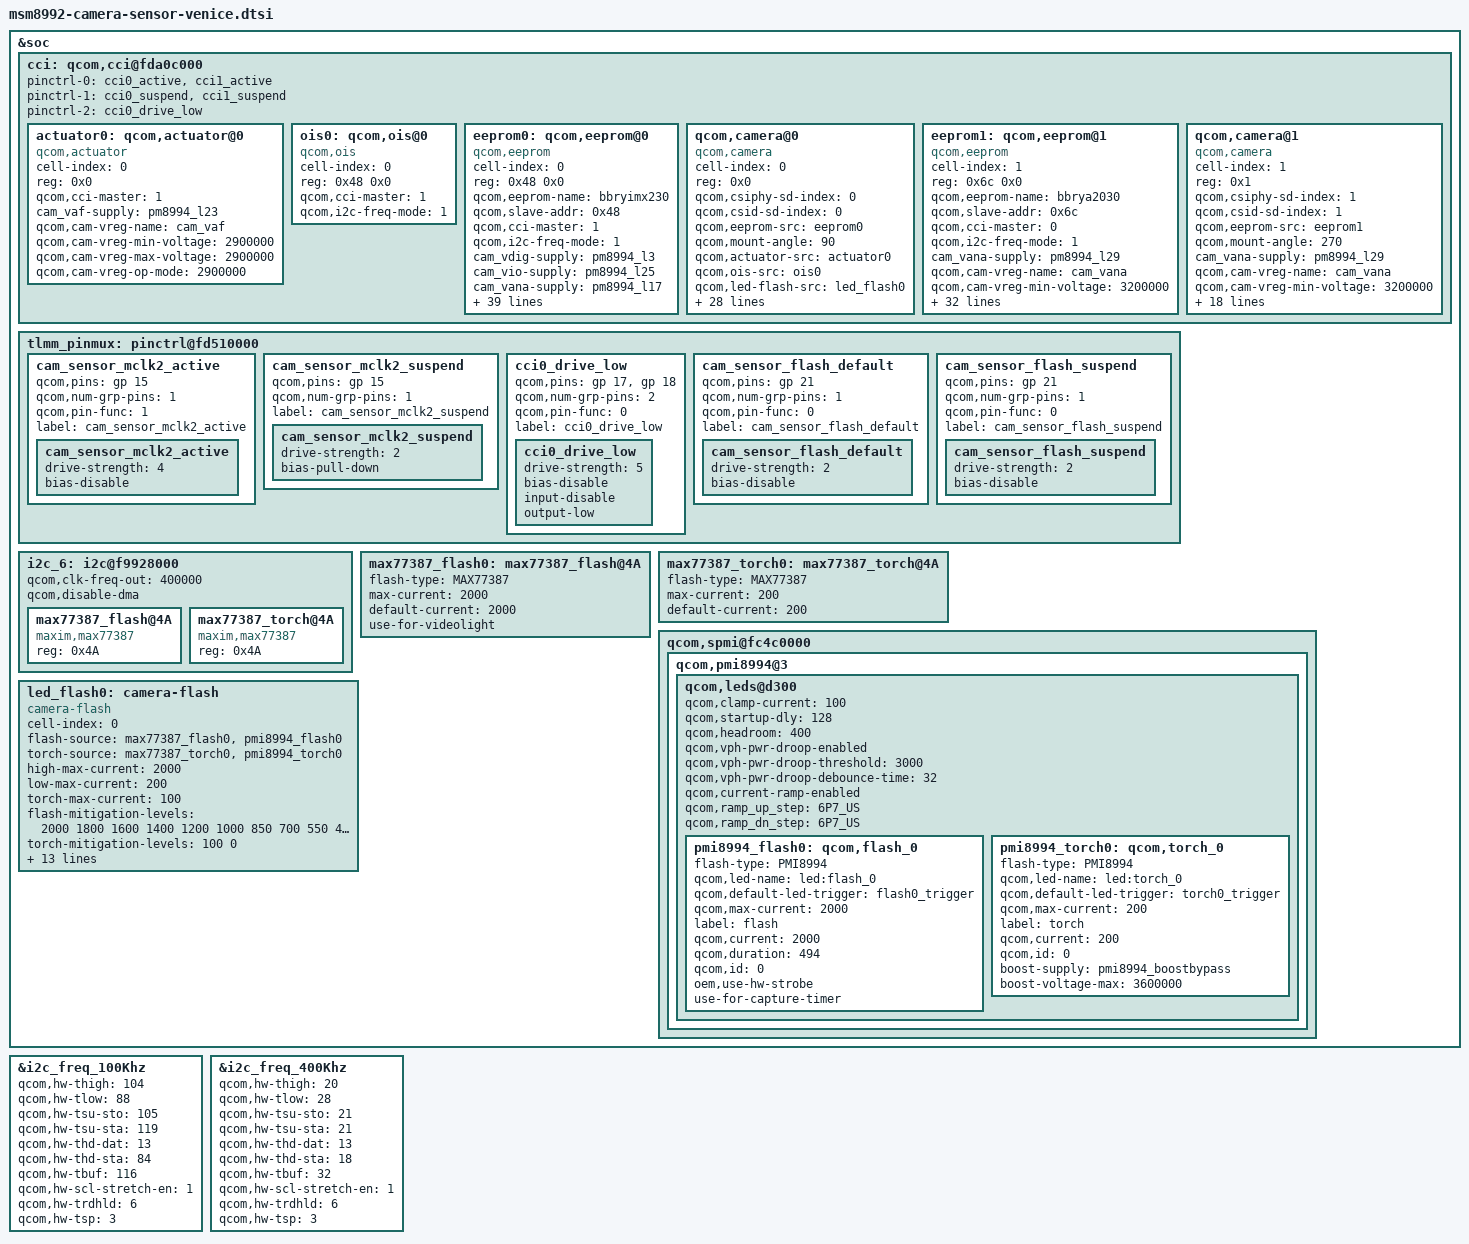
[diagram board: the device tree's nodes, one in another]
/*
 * Copyright (c) 2014, The Linux Foundation. All rights reserved.
 *
 * This program is free software; you can redistribute it and/or modify
 * it under the terms of the GNU General Public License version 2 and
 * only version 2 as published by the Free Software Foundation.
 *
 * This program is distributed in the hope that it will be useful,
 * but WITHOUT ANY WARRANTY; without even the implied warranty of
 * MERCHANTABILITY or FITNESS FOR A PARTICULAR PURPOSE.  See the
 * GNU General Public License for more details.
 */

&soc {
	cci: qcom,cci@fda0c000 {
		pinctrl-names = "cci_default", "cci_suspend", "cci0_pull_down";
			pinctrl-0 = <&cci0_active &cci1_active>;
			pinctrl-1 = <&cci0_suspend &cci1_suspend>;
			pinctrl-2 = <&cci0_drive_low>;
	};

	tlmm_pinmux: pinctrl@fd510000 {
		cam_sensor_mclk2_active {
			/* MCLK2 */
			qcom,pins = <&gp 15>;
			qcom,num-grp-pins = <1>;
			qcom,pin-func = <1>;
			label = "cam_sensor_mclk2_active";
			/* active state */
			cam_sensor_mclk2_active: cam_sensor_mclk2_active {
				drive-strength = <4>; /* 4 MA */
				bias-disable; /* No PULL */
			};
		};

		cam_sensor_mclk2_suspend {
			/* MCLK2 */
			qcom,pins = <&gp 15>;
			qcom,num-grp-pins = <1>;
			label = "cam_sensor_mclk2_suspend";
			/* suspend state */
			cam_sensor_mclk2_suspend: cam_sensor_mclk2_suspend {
				drive-strength = <2>; /* 2 MA */
				bias-pull-down; /* PULL DOWN */
			};
		};

		cci0_drive_low {
			/* CLK, DATA */
			qcom,pins = <&gp 17>, <&gp 18>;
			qcom,num-grp-pins = <2>;
			qcom,pin-func = <0>;
			label = "cci0_drive_low";
			/*pre suspended state */
			cci0_drive_low: cci0_drive_low {
				drive-strength = <5>; /* 5 MA */
				bias-disable; /* No PULL */
				input-disable;
				output-low;
			};
		};

		cam_sensor_flash_default {
			qcom,pins = <&gp 21>;
			qcom,num-grp-pins = <1>;
			qcom,pin-func = <0>;
			label = "cam_sensor_flash_default";
			cam_sensor_flash_default:cam_sensor_flash_default {
				drive-strength = <2>;
				bias-disable;
			};
		};

		cam_sensor_flash_suspend {
			qcom,pins = <&gp 21>;
			qcom,num-grp-pins = <1>;
			qcom,pin-func = <0>;
			label = "cam_sensor_flash_suspend";
			cam_sensor_flash_suspend:cam_sensor_flash_suspend {
				drive-strength = <2>;
				bias-disable;
			};
		};
	};

	i2c_6: i2c@f9928000 {
		qcom,clk-freq-out = <400000>;
		qcom,disable-dma;

		max77387_flash@4A {
			compatible = "maxim,max77387";
			reg = <0x4A>; /* i2c slave address */
		};

		max77387_torch@4A {
			compatible = "maxim,max77387";
			reg = <0x4A>; /* i2c slave address */
		};
	};

	max77387_flash0: max77387_flash@4A {
		flash-type = "MAX77387";
		max-current = <2000>;
		default-current = <2000>;
		use-for-videolight;
	};

	max77387_torch0: max77387_torch@4A {
		flash-type = "MAX77387";
		max-current = <200>;
		default-current = <200>;
	};

	qcom,spmi@fc4c0000 {
		qcom,pmi8994@3 {
			qcom,leds@d300 {
				qcom,clamp-current = <100>;
				qcom,startup-dly = <128>;
				qcom,headroom = <400>;
				qcom,vph-pwr-droop-enabled;
				qcom,vph-pwr-droop-threshold = <3000>;
				qcom,vph-pwr-droop-debounce-time = <32>;
				qcom,current-ramp-enabled;
				qcom,ramp_up_step = "6P7_US";
				qcom,ramp_dn_step = "6P7_US";
				/delete-property/ qcom,thermal-derate-enabled;
				/delete-property/ qcom,headroom-sense-ch0-enabled;
				/delete-property/ qcom,headroom-sense-ch1-enabled;
				/delete-property/ qcom,power-detect-enabled;

				pmi8994_flash0: qcom,flash_0 {
					flash-type = "PMI8994";
					qcom,led-name = "led:flash_0";
					qcom,default-led-trigger =
							"flash0_trigger";
					qcom,max-current = <2000>;
					label = "flash";
					qcom,current = <2000>;
					qcom,duration = <494>;
					qcom,id = <0>;
					oem,use-hw-strobe;
					use-for-capture-timer;
				};

				pmi8994_torch0: qcom,torch_0 {
					flash-type = "PMI8994";
					qcom,led-name = "led:torch_0";
					qcom,default-led-trigger =
							"torch0_trigger";
					qcom,max-current = <200>;
					label = "torch";
					qcom,current = <200>;
					qcom,id = <0>;
					boost-supply= <&pmi8994_boostbypass>;
					boost-voltage-max = <3600000>;
				};

				/delete-node/ pmi8994_torch1;
				/delete-node/ pmi8994_flash1;
			};
		};
	};

	led_flash0: camera-flash {
		cell-index = <0>;
		compatible = "camera-flash";
		flash-source = <&max77387_flash0 &pmi8994_flash0>;
		torch-source = <&max77387_torch0 &pmi8994_torch0>;
		high-max-current = <2000>;
		low-max-current = <200>;
		torch-max-current = <100>;
		flash-mitigation-levels = <2000 1800 1600 1400 1200 1000
						850 700 550 400 200 100 0>;
		torch-mitigation-levels = <100 0>;
		curve_mA_values = <0 100 200 400 550 700
								850 1000 1200 1400 1600 1800 2000>;
		/* relative flux values are 16.16 fixed point */
		curve_rel_flux_values = <0 5085 9510 18173 23917 29755
								35122 40113 46327 52448 57438 61487 65536>;
		preflash-divisor = <10>;

		pinctrl-names = "cam_flash_default", "cam_flash_suspend";
		pinctrl-0 = <&cam_sensor_flash_default>;
		pinctrl-1 = <&cam_sensor_flash_suspend>;
		gpios = <&msm_gpio 21 0>;
		qcom,gpio-flash-now = <0>;
		qcom,gpio-req-tbl-num = <0>;
		qcom,gpio-req-tbl-flags = <0>;
		qcom,gpio-req-tbl-label = "FLASH_NOW";
		vdd-supply = <&pm8994_l30>;
	};
};

&cci {
	actuator0: qcom,actuator@0 {
		cell-index = <0>;
		reg = <0x0>;
		compatible = "qcom,actuator";
		qcom,cci-master = <1>;
		cam_vaf-supply = <&pm8994_l23>;
		qcom,cam-vreg-name = "cam_vaf";
		qcom,cam-vreg-min-voltage = <2900000>;
		qcom,cam-vreg-max-voltage = <2900000>;
		qcom,cam-vreg-op-mode = <2900000>;
	};

	ois0: qcom,ois@0 {
		cell-index = <0>;
		reg = <0x48 0x0>;
		compatible = "qcom,ois";
		qcom,cci-master = <1>;
		qcom,i2c-freq-mode = <1>;
	};

	eeprom0: qcom,eeprom@0 {
		cell-index = <0>;
		reg = <0x48 0x0>;
		qcom,eeprom-name = "bbryimx230";
		compatible = "qcom,eeprom";
		qcom,slave-addr = <0x48>;
		qcom,cci-master = <1>;
		qcom,i2c-freq-mode = <1>;
		cam_vdig-supply = <&pm8994_l3>;
		cam_vio-supply = <&pm8994_l25>;
		cam_vana-supply = <&pm8994_l17>;
		cam_vaf-supply = <&pm8994_l23>;
		qcom,cam-vreg-name = "cam_vaf", "cam_vdig", "cam_vio", "cam_vana";
		qcom,cam-vreg-min-voltage = <2900000 1100000 1850000 2825000>;
		qcom,cam-vreg-max-voltage = <2900000 1100000 1850000 2825000>;
		qcom,cam-vreg-op-mode = <2900000 1100000 1850000 2825000>;
		qcom,gpio-no-mux = <0>;
		pinctrl-names = "cam_default", "cam_suspend";
		pinctrl-0 = <&cam_sensor_mclk0_active &cam_sensor_rear_active>;
		pinctrl-1 = <&cam_sensor_mclk0_suspend &cam_sensor_rear_suspend>;
		gpios = <&msm_gpio 13 0>,
			<&msm_gpio 92 0>;
		qcom,gpio-reset = <1>;
		qcom,gpio-req-tbl-num = <0 1>;
		qcom,gpio-req-tbl-flags = <1 0>;
		qcom,gpio-req-tbl-label = "CAMIF_MCLK0",
							"CAM_RESET0";
		qcom,cam-power-seq-type = "sensor_gpio",
			"sensor_vreg",
			"sensor_vreg",
			"sensor_vreg",
			"sensor_vreg",
			"sensor_clk",
			"sensor_gpio";
		qcom,cam-power-seq-val = "sensor_gpio_reset",
			"cam_vio",
			"cam_vaf",
			"cam_vana",
			"cam_vdig",
			"sensor_cam_mclk",
			"sensor_gpio_reset";
		qcom,cam-power-seq-cfg-val = <0 0 0 0 0 24000000 1>;
		qcom,cam-power-seq-delay = <1 4 4 4 4 4 40>;
		qcom,cam-powerdown-seq-type = "sensor_gpio",
			"sensor_gpio",
			"sensor_clk",
			"sensor_vreg",
			"sensor_vreg",
			"sensor_vreg",
			"sensor_vreg";
		qcom,cam-powerdown-seq-val = "sensor_gpio_reset",
			"sensor_gpio_reset",
			"sensor_cam_mclk",
			"cam_vdig",
			"cam_vana",
			"cam_vaf",
			"cam_vio";
		qcom,cam-powerdown-seq-cfg-val = <1 0 0 0 0 0 0 >;
		qcom,cam-powerdown-seq-delay = < 4 4 4 4 4 4 4>;
		status = "ok";
		clocks = <&clock_mmss clk_mclk0_clk_src>,
				<&clock_mmss clk_camss_mclk0_clk>;
		clock-names = "cam_src_clk", "cam_clk";
	};

	qcom,camera@0 {
		cell-index = <0>;
		compatible = "qcom,camera";
		reg = <0x0>;
		qcom,csiphy-sd-index = <0>;
		qcom,csid-sd-index = <0>;
		qcom,eeprom-src = <&eeprom0>;
		qcom,mount-angle = <90>;
		qcom,actuator-src = <&actuator0>;
		qcom,ois-src = <&ois0>;
		qcom,led-flash-src = <&led_flash0>;
		cam_vdig-supply = <&pm8994_l3>;
		cam_vio-supply = <&pm8994_l25>;
		cam_vana-supply = <&pm8994_l17>;
		cam_vaf-supply = <&pm8994_l23>;
		qcom,cam-vreg-name = "cam_vaf", "cam_vdig", "cam_vio", "cam_vana";
		qcom,cam-vreg-min-voltage = <2900000 1100000 1850000 2825000>;
		qcom,cam-vreg-max-voltage = <2900000 1100000 1850000 2825000>;
		qcom,cam-vreg-op-mode = <2900000 1100000 1850000 2825000>;
		qcom,gpio-no-mux = <0>;
		pinctrl-names = "cam_default", "cam_suspend";
		pinctrl-0 = <&cam_sensor_mclk0_active &cam_sensor_rear_active>;
		pinctrl-1 = <&cam_sensor_mclk0_suspend &cam_sensor_rear_suspend>;
		gpios = <&msm_gpio 13 0>,
			<&msm_gpio 92 0>;
		qcom,gpio-reset = <1>;
		qcom,gpio-req-tbl-num = <0 1>;
		qcom,gpio-req-tbl-flags = <1 0>;
		qcom,gpio-req-tbl-label = "CAMIF_MCLK0",
					  "CAM_RESET0";
		qcom,sensor-position = <0>;
		qcom,sensor-mode = <0>;
		qcom,cci-master = <1>;
		status = "ok";
		clocks = <&clock_mmss clk_mclk0_clk_src>,
				<&clock_mmss clk_camss_mclk0_clk>;
		clock-names = "cam_src_clk", "cam_clk";
	};

	eeprom1: qcom,eeprom@1 {
		cell-index = <1>;
		reg = <0x6c 0x0>;
		qcom,eeprom-name = "bbrya2030";
		compatible = "qcom,eeprom";
		qcom,slave-addr = <0x6c>;
		qcom,cci-master = <0>;
		qcom,i2c-freq-mode = <1>;
		cam_vana-supply = <&pm8994_l29>;
		qcom,cam-vreg-name = "cam_vana";
		qcom,cam-vreg-min-voltage = <3200000>;
		qcom,cam-vreg-max-voltage = <3200000>;
		qcom,cam-vreg-op-mode = <3200000>;
		qcom,gpio-no-mux = <0>;
		pinctrl-names = "cam_default", "cam_suspend";
		pinctrl-0 = <&cam_sensor_mclk2_active &cam_sensor_front_active>;
		pinctrl-1 = <&cam_sensor_mclk2_suspend &cam_sensor_front_suspend>;
		gpios = <&msm_gpio 15 0>,
			<&msm_gpio 104 0>;
		qcom,gpio-reset = <1>;
		qcom,gpio-req-tbl-num = <0 1>;
		qcom,gpio-req-tbl-flags = <1 0>;
		qcom,gpio-req-tbl-label = "CAMIF_MCLK2",
					  "CAM_RESET1";
		qcom,csi-lane-assign = <0x4320>;
		qcom,csi-lane-mask = <0x3>;
		qcom,cam-power-seq-type = "sensor_gpio",
			"sensor_vreg",
			"sensor_clk",
			"sensor_gpio";
		qcom,cam-power-seq-val = "sensor_gpio_reset",
			"cam_vana",
			"sensor_cam_mclk",
			"sensor_gpio_reset";
		qcom,cam-power-seq-cfg-val = <0 0 24000000 1>;
		qcom,cam-power-seq-delay = <1 4 4 30>;
		qcom,cam-powerdown-seq-type = "sensor_gpio",
			"sensor_gpio",
			"sensor_clk",
			"sensor_vreg",
			"sensor_i2c",
			"sensor_i2c";
		qcom,cam-powerdown-seq-val = "sensor_gpio_reset",
			"sensor_gpio_reset",
			"sensor_cam_mclk",
			"cam_vana",
			"sensor_gpio_custom1",
			"sensor_gpio_custom2";
		qcom,cam-powerdown-seq-cfg-val = <1 0 0 0 0 0>;
		qcom,cam-powerdown-seq-delay = <4 4 4 4 4 0>;
		clocks = <&clock_mmss clk_mclk2_clk_src>,
			<&clock_mmss clk_camss_mclk2_clk>;
		clock-names = "cam_src_clk", "cam_clk";
	};

	qcom,camera@1 {
		cell-index = <1>;
		compatible = "qcom,camera";
		reg = <0x1>;
		qcom,csiphy-sd-index = <1>;
		qcom,csid-sd-index = <1>;
		qcom,eeprom-src = <&eeprom1>;
		qcom,mount-angle = <270>;
		cam_vana-supply = <&pm8994_l29>;
		qcom,cam-vreg-name = "cam_vana";
		qcom,cam-vreg-min-voltage = <3200000>;
		qcom,cam-vreg-max-voltage = <3200000>;
		qcom,cam-vreg-op-mode = <3200000>;
		qcom,gpio-no-mux = <0>;
		pinctrl-names = "cam_default", "cam_suspend";
		pinctrl-0 = <&cam_sensor_mclk2_active &cam_sensor_front_active>;
		pinctrl-1 = <&cam_sensor_mclk2_suspend &cam_sensor_front_suspend>;
		gpios = <&msm_gpio 15 0>,
			<&msm_gpio 104 0>;
		qcom,gpio-reset = <1>;
		qcom,gpio-req-tbl-num = <0 1>;
		qcom,gpio-req-tbl-flags = <1 0>;
		qcom,gpio-req-tbl-label = "CAMIF_MCLK2",
					  "CAM_RESET1";
		qcom,sensor-position = <1>;
		qcom,sensor-mode = <0>;
		qcom,cci-master = <0>;
		status = "ok";
		clocks = <&clock_mmss clk_mclk2_clk_src>,
			<&clock_mmss clk_camss_mclk2_clk>;
		clock-names = "cam_src_clk", "cam_clk";
	};
};
&i2c_freq_100Khz {
	qcom,hw-thigh = <104>;
	qcom,hw-tlow = <88>;
	qcom,hw-tsu-sto = <105>;
	qcom,hw-tsu-sta = <119>;
	qcom,hw-thd-dat = <13>;
	qcom,hw-thd-sta = <84>;
	qcom,hw-tbuf = <116>;
	qcom,hw-scl-stretch-en = <1>;
	qcom,hw-trdhld = <6>;
	qcom,hw-tsp = <3>;
	status = "ok";
};
&i2c_freq_400Khz {
	qcom,hw-thigh = <20>;
	qcom,hw-tlow = <28>;
	qcom,hw-tsu-sto = <21>;
	qcom,hw-tsu-sta = <21>;
	qcom,hw-thd-dat = <13>;
	qcom,hw-thd-sta = <18>;
	qcom,hw-tbuf = <32>;
	qcom,hw-scl-stretch-en = <1>;
	qcom,hw-trdhld = <6>;
	qcom,hw-tsp = <3>;
	status = "ok";
};
